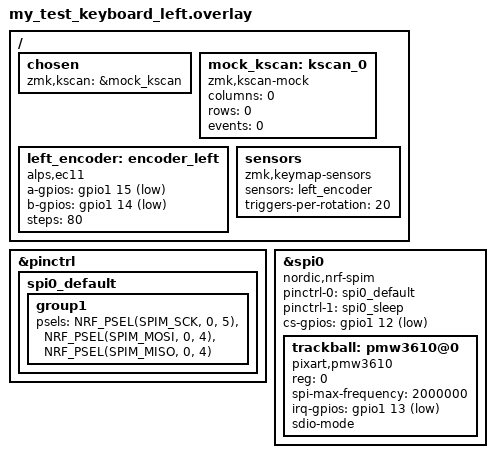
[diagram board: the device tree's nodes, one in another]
/* my_test_keyboard_left.overlay */

/ {
    /* 1. chosenノードを追加してkscanを指定 */
    chosen {
        zmk,kscan = &mock_kscan;
    };

    /* 2. ダミーのkscanを追加 (キーがなくてもビルドを通すため) */
    mock_kscan: kscan_0 {
        compatible = "zmk,kscan-mock";
        columns = <0>;
        rows = <0>;
        events = <0>;
    };

    left_encoder: encoder_left {
        compatible = "alps,ec11";
        a-gpios = <&gpio1 15 (GPIO_ACTIVE_LOW | GPIO_PULL_UP)>; 
        b-gpios = <&gpio1 14 (GPIO_ACTIVE_LOW | GPIO_PULL_UP)>;
        steps = <80>;
        status = "okay";
    };

    sensors: sensors {
        compatible = "zmk,keymap-sensors";
        sensors = <&left_encoder>;
        triggers-per-rotation = <20>;
    };
};

/* --- 以下、SPI設定などは変更なし --- */
&pinctrl {
    spi0_default: spi0_default {
        group1 {
            psels = <NRF_PSEL(SPIM_SCK, 0, 5)>,
                    <NRF_PSEL(SPIM_MOSI, 0, 4)>,
                    <NRF_PSEL(SPIM_MISO, 0, 4)>;
        };
    };
    /* ... (中略) ... */
};

&spi0 {
    status = "okay";
    compatible = "nordic,nrf-spim";
    pinctrl-0 = <&spi0_default>;
    pinctrl-1 = <&spi0_sleep>;
    pinctrl-names = "default", "sleep";
    cs-gpios = <&gpio1 12 GPIO_ACTIVE_LOW>; // NCS: P1.12 [cite: 8]

    trackball: pmw3610@0 {
        status = "okay";
        compatible = "pixart,pmw3610";
        reg = <0>;
        spi-max-frequency = <2000000>;
        irq-gpios = <&gpio1 13 (GPIO_ACTIVE_LOW | GPIO_PULL_UP)>; // MOTION: P1.13 [cite: 10]
        sdio-mode;
    };
};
